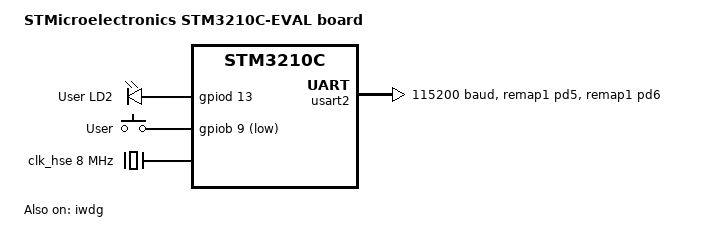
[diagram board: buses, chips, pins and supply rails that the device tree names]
/*
 * Copyright (c) 2017 Linaro Limited
 *
 * SPDX-License-Identifier: Apache-2.0
 */

/dts-v1/;
#include <st/f1/stm32f107Xc.dtsi>
#include <st/f1/stm32f107v(b-c)tx-pinctrl.dtsi>
#include <zephyr/dt-bindings/input/input-event-codes.h>

/ {
	model = "STMicroelectronics STM3210C-EVAL board";
	compatible = "st,stm3210c-eval";

	chosen {
		zephyr,console = &usart2;
		zephyr,shell-uart = &usart2;
		zephyr,sram = &sram0;
		zephyr,flash = &flash0;
	};

	leds {
		compatible = "gpio-leds";
		green_led_2: led_2 {
			gpios = <&gpiod 13 GPIO_ACTIVE_HIGH>;
			label = "User LD2";
		};
	};

	gpio_keys {
		compatible = "gpio-keys";
		user_button: button {
			label = "User";
			gpios = <&gpiob 9 GPIO_ACTIVE_LOW>;
			zephyr,code = <INPUT_KEY_0>;
		};
	};

	aliases {
		led0 = &green_led_2;
		sw0 = &user_button;
		watchdog0 = &iwdg;
	};
};

&clk_hse {
	hse-bypass;
	clock-frequency = <DT_FREQ_M(8)>; /* STLink 8MHz clock */
	status = "okay";
};

&pll {
	mul = <9>;
	prediv = <1>;
	clocks = <&clk_hse>;
	status = "okay";
};

&rcc {
	clocks = <&pll>;
	clock-frequency = <DT_FREQ_M(72)>;
	ahb-prescaler = <1>;
	apb1-prescaler = <2>;
	apb2-prescaler = <1>;
};

&usart2 {
	pinctrl-0 = <&usart2_tx_remap1_pd5 &usart2_rx_remap1_pd6>;
	pinctrl-names = "default";
	current-speed = <115200>;
	status = "okay";
};

&iwdg {
	status = "okay";
};
